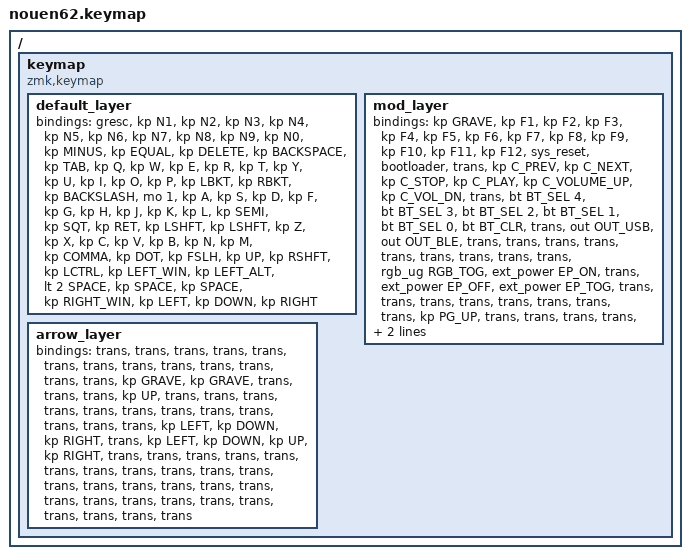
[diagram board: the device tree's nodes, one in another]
/*
 * Copyright (c) 2021 Nick Winans
 *
 * SPDX-License-Identifier: MIT
 */

#include <behaviors.dtsi>
#include <dt-bindings/zmk/bt.h>
#include <dt-bindings/zmk/ext_power.h>
#include <dt-bindings/zmk/keys.h>
#include <dt-bindings/zmk/outputs.h>
#include <dt-bindings/zmk/rgb.h>

/ {
    keymap {
        compatible = "zmk,keymap";

        default_layer {
            // ----------------------------------------------------------------------------------------------------------
            // | F1  | ESC |  1  |  2  |  3  |  4  |  5  |  6  |  7  |  8  |  9  |  0  |  -  |  =  |   BKSP   | HOME    |
            // | F2  | TAB  |  Q  |  W  |  E  |  R  |  T  |  Y  |  U  |  I  |  O  |  P  |  [  |  ]  |   "|"   | PG UP   |
            // | F3  | CAPS  |  A  |  S  | D  |  F  |  G  |  H  |  J  |  K  |  L  |  ;  |  '  |     ENTER     | PG DOWN |
            // | F4  |  SHIFT | SHIFT |  Z  |  X  |  C  |  V  |  B  |  N  |  M  |  ,  |  .  |  /  |   SHIFT  |  UP   | END     |
            // | F5  |  CTL  |  ALT  |  WIN  |                SPACE MO(1)   | MO(1)|  MO(2)  |  LEFT  |  DOWN | RIGHT   |
            // ----------------------------------------------------------------------------------------------------------

            bindings = <
&gresc  &kp N1  &kp N2  &kp N3  &kp N4  &kp N5  &kp N6  &kp N7  &kp N8  &kp N9  &kp N0  &kp MINUS  &kp EQUAL  &kp DELETE  &kp BACKSPACE  &kp TAB  &kp Q  &kp W  &kp E  &kp R  &kp T  &kp Y  &kp U  &kp I  &kp O  &kp P  &kp LBKT  &kp RBKT  &kp BACKSLASH  &mo 1  &kp A  &kp S  &kp D  &kp F  &kp G  &kp H  &kp J  &kp K  &kp L  &kp SEMI  &kp SQT  &kp RET  &kp LSHFT  &kp LSHFT  &kp Z  &kp X  &kp C  &kp V  &kp B  &kp N  &kp M  &kp COMMA  &kp DOT  &kp FSLH  &kp UP  &kp RSHFT  &kp LCTRL  &kp LEFT_WIN  &kp LEFT_ALT  &lt 2 SPACE  &kp SPACE  &kp SPACE  &kp RIGHT_WIN  &kp LEFT  &kp DOWN  &kp RIGHT
            >;
        };

        mod_layer {
            // ----------------------------------------------------------------------------------------------------------------
            // |        |    | BT 1|BT 2 |BT 3 |BT 4 |     |     |     |     |     |     |     |     |BT CLR |         |
            // |        |    | RST | BOOT|     |     |     |     |     |     |     |     |     |     |       |         |
            // |        |    | USB | BLE |     |     |     |     |     |     |     |     |     |     |RGB TOG|         |
            // |        |    |EP_ON|EP_OFF|EP_TOG|     |     |     |     |     |     |     |     |     |       |         |
            // |        |    |     |     |                                               |     |     |       |         |
            // ----------------------------------------------------------------------------------------------------------------

            bindings = <
&kp GRAVE  &kp F1  &kp F2  &kp F3  &kp F4  &kp F5  &kp F6  &kp F7  &kp F8  &kp F9  &kp F10  &kp F11  &kp F12  &sys_reset  &bootloader  &trans  &kp C_PREV  &kp C_NEXT  &kp C_STOP  &kp C_PLAY  &kp C_VOLUME_UP  &kp C_VOL_DN  &trans  &bt BT_SEL 4  &bt BT_SEL 3  &bt BT_SEL 2  &bt BT_SEL 1  &bt BT_SEL 0  &bt BT_CLR  &trans  &out OUT_USB  &out OUT_BLE  &trans  &trans  &trans  &trans  &trans  &trans  &trans  &trans  &trans  &rgb_ug RGB_TOG  &ext_power EP_ON  &trans  &ext_power EP_OFF  &ext_power EP_TOG  &trans  &trans  &trans  &trans  &trans  &trans  &trans  &trans  &kp PG_UP  &trans  &trans  &trans  &trans  &trans  &trans  &trans  &trans  &kp HOME  &kp PAGE_DOWN  &kp END
            >;
        };

        arrow_layer {
            // ----------------------------------------------------------------------------------------------------------------
            // |        |    |     |     |     |     |     |     |     |     |     |     |     |     |     |   `~    |
            // |        |    |     |     |     |     |     |     |     |     |     |     |     |     |     |         |
            // |        |    |     |     |     |     |     |LEFT |DOWN |  UP |RIGHT|     |     |     |     |         |
            // |        |    |     |     |     |     |     |     |     |     |     |     |     |     |     |         |
            // |        |    |     |     |                                               |     |     |     |         |
            // ----------------------------------------------------------------------------------------------------------------

            bindings = <
&trans  &trans  &trans  &trans  &trans  &trans  &trans  &trans  &trans  &trans  &trans  &trans  &trans  &kp GRAVE  &kp GRAVE  &trans  &trans  &trans  &kp UP  &trans  &trans  &trans  &trans  &trans  &trans  &trans  &trans  &trans  &trans  &trans  &trans  &kp LEFT  &kp DOWN  &kp RIGHT  &trans  &kp LEFT  &kp DOWN  &kp UP  &kp RIGHT  &trans  &trans  &trans  &trans  &trans  &trans  &trans  &trans  &trans  &trans  &trans  &trans  &trans  &trans  &trans  &trans  &trans  &trans  &trans  &trans  &trans  &trans  &trans  &trans  &trans  &trans  &trans
            >;
        };
    };
};
